# f1c100s register map
Vendor: Allwinner; File version: 1.0
Registers are 32-bit, read-write, reset 0x0 unless marked. A register's access mark holds for its fields unless they carry their own. Offsets are from the block's base; [hi:lo] are bit positions; 'fields as' and 'values as' point back to an identical list.

## CCU — Clock Control Unit - PLLs, Bus Clocks, Gating and Reset
Base 0x01C20000
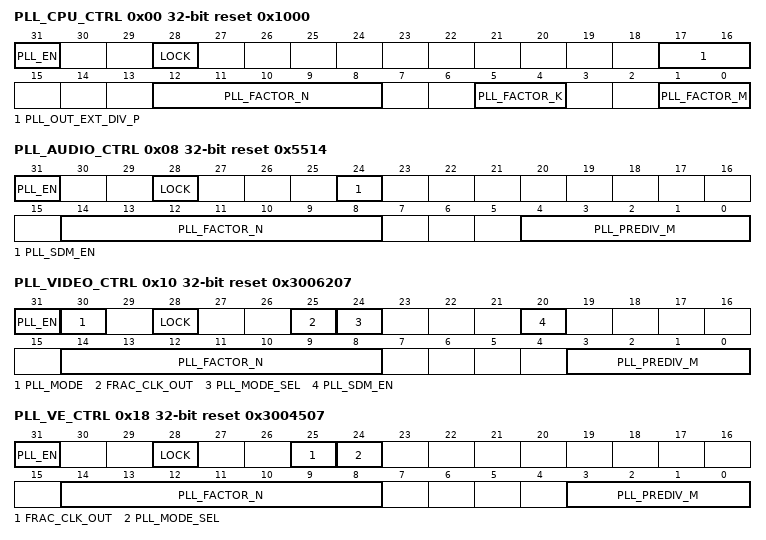
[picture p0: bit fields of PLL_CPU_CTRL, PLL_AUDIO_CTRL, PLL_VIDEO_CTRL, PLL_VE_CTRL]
0x00 PLL_CPU_CTRL reset 0x1000 — PLL CPU Control Register
  [31] PLL_EN — PLL Enable
  [28] LOCK ro — PLL Lock Status (read-only)
  [17:16] PLL_OUT_EXT_DIV_P — PLL Output External Divider P: 00=/1, 01=/2, 10=/4
  [12:8] PLL_FACTOR_N — PLL Factor N (N=Factor+1, range 1-32)
  [5:4] PLL_FACTOR_K — PLL Factor K (K=Factor+1, range 1-4)
  [1:0] PLL_FACTOR_M — PLL Factor M (M=Factor+1, range 1-4)
0x08 PLL_AUDIO_CTRL reset 0x5514 — PLL Audio Control Register
  [31] PLL_EN — PLL Enable
  [28] LOCK ro — PLL Lock Status
  [24] PLL_SDM_EN — PLL Sigma-Delta Modulation Enable
  [14:8] PLL_FACTOR_N — PLL Factor N (N=Factor+1, range 1-128)
  [4:0] PLL_PREDIV_M — PLL Pre-div Factor M (M=Factor+1, range 1-32)
0x10 PLL_VIDEO_CTRL reset 0x3006207 — PLL Video Control Register
  [31] PLL_EN — PLL Enable
  [30] PLL_MODE — PLL Mode: 0=Manual, 1=Auto (Controlled by DE)
  [28] LOCK ro — PLL Lock Status
  [25] FRAC_CLK_OUT — Fractional Clock Output: 0=270MHz, 1=297MHz
  [24] PLL_MODE_SEL — PLL Mode Select: 0=Fractional, 1=Integer
  [20] PLL_SDM_EN — PLL Sigma-Delta Modulation Enable
  [14:8] PLL_FACTOR_N — PLL Factor N (N=Factor+1, range 1-128)
  [3:0] PLL_PREDIV_M — PLL Pre-div Factor M (M=Factor+1, range 1-16)
0x18 PLL_VE_CTRL reset 0x3004507 — PLL VE Control Register
  [31] PLL_EN — PLL Enable
  [28] LOCK ro — PLL Lock Status
  [25] FRAC_CLK_OUT — Fractional Clock Output: 0=270MHz, 1=297MHz
  [24] PLL_MODE_SEL — PLL Mode Select: 0=Fractional, 1=Integer
  [14:8] PLL_FACTOR_N — PLL Factor N (N=Factor+1, range 1-128)
  [3:0] PLL_PREDIV_M — PLL Pre-div Factor M (M=Factor+1, range 1-16)
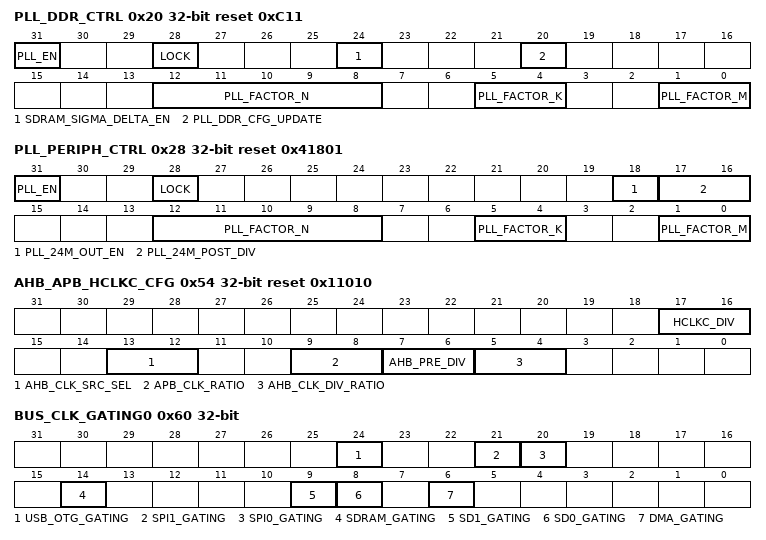
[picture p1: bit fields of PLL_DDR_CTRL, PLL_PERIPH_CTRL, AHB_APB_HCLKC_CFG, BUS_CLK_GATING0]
0x20 PLL_DDR_CTRL reset 0xC11 — PLL DDR Control Register
  [31] PLL_EN — PLL Enable
  [28] LOCK ro — PLL Lock Status
  [24] SDRAM_SIGMA_DELTA_EN — SDRAM Sigma-Delta Enable
  [20] PLL_DDR_CFG_UPDATE — PLL DDR Configuration Update
  [12:8] PLL_FACTOR_N — PLL Factor N (N=Factor+1, range 1-32)
  [5:4] PLL_FACTOR_K — PLL Factor K (K=Factor+1, range 1-4)
  [1:0] PLL_FACTOR_M — PLL Factor M (M=Factor+1, range 1-4)
0x28 PLL_PERIPH_CTRL reset 0x41801 — PLL Peripheral Control Register
  [31] PLL_EN — PLL Enable
  [28] LOCK ro — PLL Lock Status
  [18] PLL_24M_OUT_EN — PLL 24MHz Output Enable
  [17:16] PLL_24M_POST_DIV — PLL 24M Output Clock Post Divider (1/2/3/4)
  [12:8] PLL_FACTOR_N — PLL Factor N (N=Factor+1, range 1-32)
  [5:4] PLL_FACTOR_K — PLL Factor K (K=Factor+1, range 1-4)
  [1:0] PLL_FACTOR_M — PLL Factor M (M=Factor+1, range 1-4)
0x50 CPU_CLK_SRC reset 0x10000 — CPU Clock Source Register
  [17:16] CPU_CLK_SRC_SEL — CPU Clock Source Select: 00=LOSC, 01=OSC24M, 1X=PLL_CPU
0x54 AHB_APB_HCLKC_CFG reset 0x11010 — AHB/APB/HCLKC Configuration Register
  [17:16] HCLKC_DIV — HCLKC Clock Divide Ratio: 00=/1, 01=/2, 10=/3, 11=/4
  [13:12] AHB_CLK_SRC_SEL — AHB Clock Source: 00=LOSC, 01=OSC24M, 10=CPUCLK, 11=PLL_PERIPH/AHB_PREDIV
  [9:8] APB_CLK_RATIO — APB Clock Divide Ratio: 0X=/2, 10=/4, 11=/8
  [7:6] AHB_PRE_DIV — AHB Clock Pre-divide Ratio: 00=/1, 01=/2, 10=/3, 11=/4
  [5:4] AHB_CLK_DIV_RATIO — AHB Clock Divide Ratio: 00=/1, 01=/2, 10=/4, 11=/8
0x60 BUS_CLK_GATING0 — Bus Clock Gating Register 0
  [24] USB_OTG_GATING — Gating Clock For USB-OTG
  [21] SPI1_GATING — Gating Clock For SPI1
  [20] SPI0_GATING — Gating Clock For SPI0
  [14] SDRAM_GATING — Gating Clock For SDRAM
  [9] SD1_GATING — Gating Clock For SD1
  [8] SD0_GATING — Gating Clock For SD0
  [6] DMA_GATING — Gating Clock For DMA
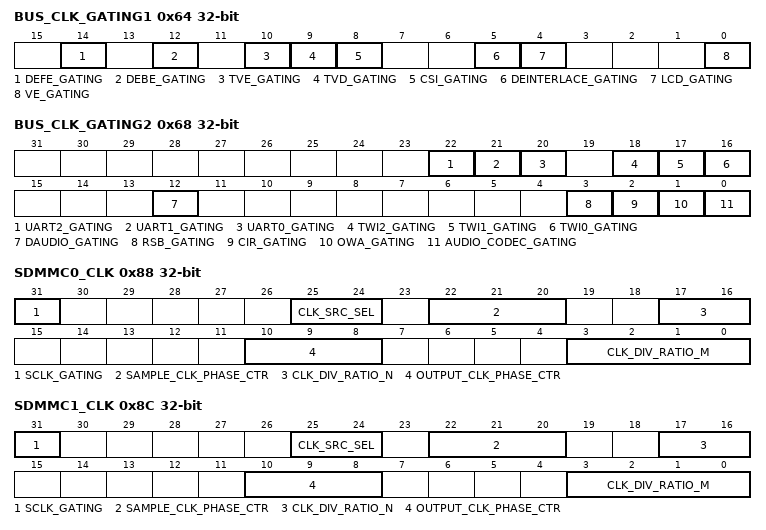
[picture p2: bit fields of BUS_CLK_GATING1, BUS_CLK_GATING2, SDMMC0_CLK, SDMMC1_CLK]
0x64 BUS_CLK_GATING1 — Bus Clock Gating Register 1
  [14] DEFE_GATING — Gating Clock For DEFE
  [12] DEBE_GATING — Gating Clock For DEBE
  [10] TVE_GATING — Gating Clock For TVE
  [9] TVD_GATING — Gating Clock For TVD
  [8] CSI_GATING — Gating Clock For CSI
  [5] DEINTERLACE_GATING — Gating Clock For DE Interlacer
  [4] LCD_GATING — Gating Clock For LCD
  [0] VE_GATING — Gating Clock For VE
0x68 BUS_CLK_GATING2 — Bus Clock Gating Register 2
  [22] UART2_GATING — Gating Clock For UART2
  [21] UART1_GATING — Gating Clock For UART1
  [20] UART0_GATING — Gating Clock For UART0
  [18] TWI2_GATING — Gating Clock For TWI2
  [17] TWI1_GATING — Gating Clock For TWI1
  [16] TWI0_GATING — Gating Clock For TWI0
  [12] DAUDIO_GATING — Gating Clock For DAUDIO
  [3] RSB_GATING — Gating Clock For RSB
  [2] CIR_GATING — Gating Clock For CIR
  [1] OWA_GATING — Gating Clock For OWA
  [0] AUDIO_CODEC_GATING — Gating Clock For AUDIOCODEC
0x88 SDMMC0_CLK — SDMMC0 Clock Register
  [31] SCLK_GATING — Gating Special Clock
  [25:24] CLK_SRC_SEL — Clock Source Select: 00=OSC24M, 01=PLL_PERIPH
  [22:20] SAMPLE_CLK_PHASE_CTR — Sample Clock Phase Control (0-7)
  [17:16] CLK_DIV_RATIO_N — Clock Pre-Divide Ratio N (2^n, divider 1/2/4/8)
  [10:8] OUTPUT_CLK_PHASE_CTR — Output Clock Phase Control (0-7)
  [3:0] CLK_DIV_RATIO_M — Clock Divide Ratio M (m+1, divider 1-16)
0x8C SDMMC1_CLK — SDMMC1 Clock Register
  fields as SDMMC0_CLK
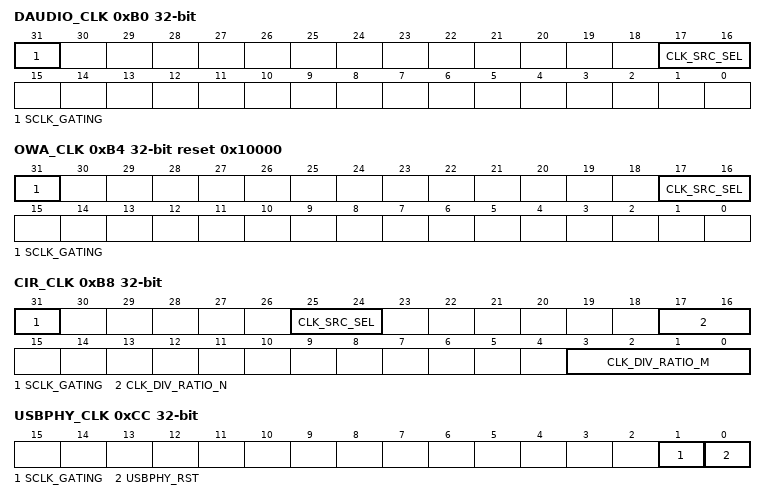
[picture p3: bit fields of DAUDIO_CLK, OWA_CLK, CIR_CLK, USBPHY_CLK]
0xB0 DAUDIO_CLK — DAUDIO Clock Register
  [31] SCLK_GATING — Gating Special Clock
  [17:16] CLK_SRC_SEL — Clock Source: 00=PLL_AUDIO(8X), 01=PLL_AUDIO(8X)/2, 10=PLL_AUDIO(8X)/4, 11=PLL_AUDIO(8X)/8
0xB4 OWA_CLK reset 0x10000 — OWA Clock Register
  [31] SCLK_GATING — Gating Special Clock
  [17:16] CLK_SRC_SEL — Clock Source: 00=PLL2(8X), 01=PLL2(8X)/2, 10=PLL2(8X)/4, 11=PLL2(8X)/8
0xB8 CIR_CLK — CIR Clock Register
  [31] SCLK_GATING — Gating Special Clock
  [25:24] CLK_SRC_SEL — Clock Source Select: 00=LOSC, 01=OSC24M
  [17:16] CLK_DIV_RATIO_N — Clock Pre-divide Ratio N (2^n, divider 1/2/4/8)
  [3:0] CLK_DIV_RATIO_M — Clock Divide Ratio M (m+1, divider 1-16)
0xCC USBPHY_CLK — USBPHY Clock Register
  [1] SCLK_GATING — USBPHY 24MHz Clock Gating
  [0] USBPHY_RST — USB PHY Reset Control: 0=Assert, 1=De-assert
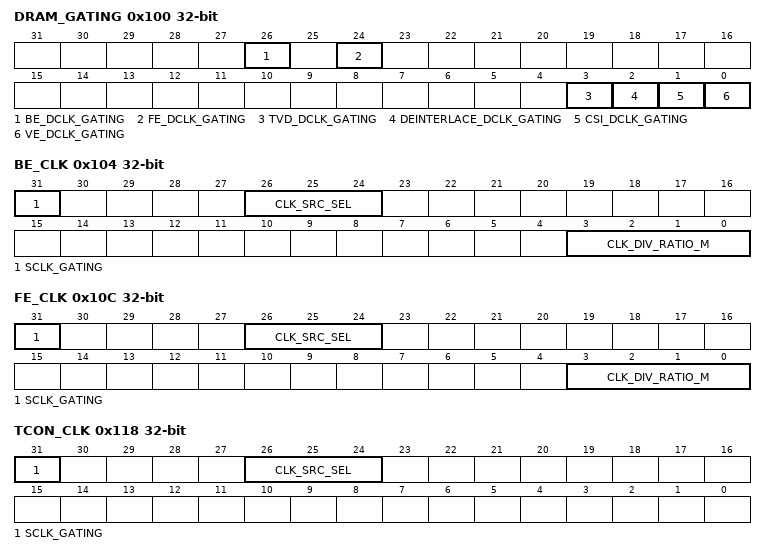
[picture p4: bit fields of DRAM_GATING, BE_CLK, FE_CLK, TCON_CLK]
0x100 DRAM_GATING
  [26] BE_DCLK_GATING — Gating DRAM SCLK(1X) For BE
  [24] FE_DCLK_GATING — Gating DRAM SCLK(1X) For FE
  [3] TVD_DCLK_GATING — Gating DRAM SCLK(1X) For TVD
  [2] DEINTERLACE_DCLK_GATING — Gating DRAM SCLK(1X) For DEINTERLACE
  [1] CSI_DCLK_GATING — Gating DRAM SCLK(1X) For CSI
  [0] VE_DCLK_GATING — Gating DRAM SCLK(1X) For VE
0x104 BE_CLK — BE Clock Register
  [31] SCLK_GATING — Gating Special Clock
  [26:24] CLK_SRC_SEL — Clock Source: 000=PLL_VIDEO, 010=PLL_PERIPH
  [3:0] CLK_DIV_RATIO_M — Clock Divide Ratio M (m+1, divider 1-16)
0x10C FE_CLK — FE Clock Register
  fields as BE_CLK
0x118 TCON_CLK — TCON Clock Register
  [31] SCLK_GATING — Gating Special Clock
  [26:24] CLK_SRC_SEL — Clock Source: 000=PLL_VIDEO(1X), 010=PLL_VIDEO(2X)
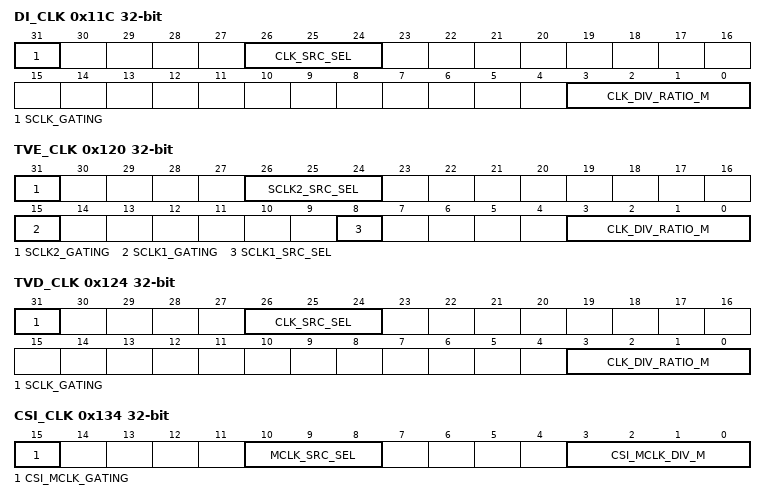
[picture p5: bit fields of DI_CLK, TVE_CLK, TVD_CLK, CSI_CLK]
0x11C DI_CLK — De-interlacer Clock Register
  [31] SCLK_GATING — Gating Special Clock
  [26:24] CLK_SRC_SEL — Clock Source: 000=PLL_VIDEO(1X), 010=PLL_VIDEO(2X)
  [3:0] CLK_DIV_RATIO_M — Clock Divide Ratio M (m+1, divider 1-16)
0x120 TVE_CLK — TVE Clock Register
  [31] SCLK2_GATING — Gating Special Clock 2
  [26:24] SCLK2_SRC_SEL — SClock2 Source: 000=PLL_VIDEO(1X), 010=PLL_VIDEO(2X)
  [15] SCLK1_GATING — Gating Special Clock 1
  [8] SCLK1_SRC_SEL — SClock1 Source: 0=TVE_SCLK2, 1=TVE_SCLK2/2
  [3:0] CLK_DIV_RATIO_M — Clock Divide Ratio M (m+1, divider 1-16)
0x124 TVD_CLK — TVD Clock Register
  [31] SCLK_GATING — Gating Special Clock
  [26:24] CLK_SRC_SEL — Clock Source: 000=PLL_VIDEO(1X), 001=OSC24M, 010=PLL_VIDEO(2X)
  [3:0] CLK_DIV_RATIO_M — Clock Divide Ratio M (m+1, divider 1-16)
0x134 CSI_CLK — CSI Clock Register
  [15] CSI_MCLK_GATING — Gating Master Clock
  [10:8] MCLK_SRC_SEL — Master Clock Source: 000=PLL_VIDEO(1X), 101=OSC24M
  [3:0] CSI_MCLK_DIV_M — CSI Master Clock Divide Ratio M (m+1, divider 1-16)
0x13C VE_CLK — VE Clock Register
  [31] SCLK_GATING — Gating Special Clock (SCLK=PLL_VE output)
0x140 AUDIO_CODEC_CLK — Audio Codec Clock Register
  [31] SCLK_GATING — Gating Special Clock (SCLK=PLL_AUDIO output)
0x144 AVS_CLK — AVS Clock Register
  [31] SCLK_GATING — Gating Special Clock (SCLK=OSC24M)
0x200 PLL_STABLE_TIME0 reset 0xFF — PLL Stable Time Register 0
  [15:0] PLL_LOCK_TIME — PLL Lock Time (Unit: us)
0x204 PLL_STABLE_TIME1 reset 0xFF — PLL Stable Time Register 1
  [15:0] PLL_CPU_LOCK_TIME — PLL CPU Lock Time (Unit: us)
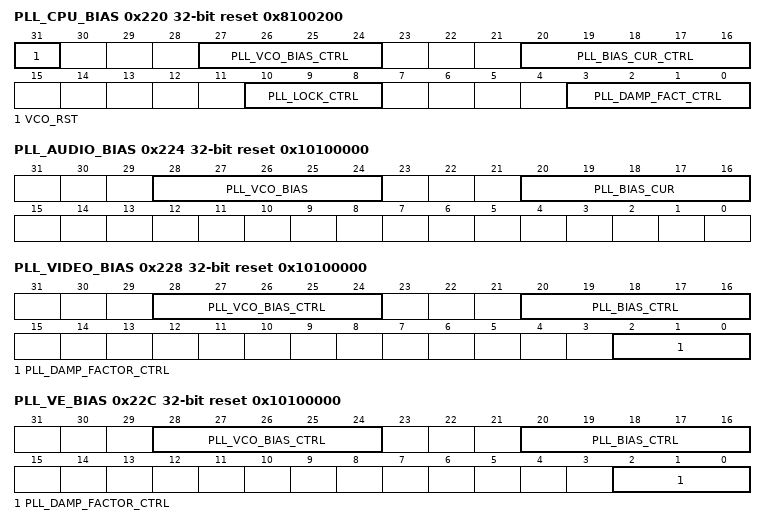
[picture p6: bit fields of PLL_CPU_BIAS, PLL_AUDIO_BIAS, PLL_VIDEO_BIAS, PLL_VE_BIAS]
0x220 PLL_CPU_BIAS reset 0x8100200
  [31] VCO_RST — VCO Reset In
  [27:24] PLL_VCO_BIAS_CTRL — PLL VCO Bias Control[3:0]
  [20:16] PLL_BIAS_CUR_CTRL — PLL Bias Current Control[4:0]
  [10:8] PLL_LOCK_CTRL — PLL Lock Time Control[2:0]
  [3:0] PLL_DAMP_FACT_CTRL — PLL Damping Factor Control[3:0]
0x224 PLL_AUDIO_BIAS reset 0x10100000
  [28:24] PLL_VCO_BIAS — PLL VCO Bias Current[4:0]
  [20:16] PLL_BIAS_CUR — PLL Bias Current[4:0]
0x228 PLL_VIDEO_BIAS reset 0x10100000
  [28:24] PLL_VCO_BIAS_CTRL — PLL VCO Bias Control[4:0]
  [20:16] PLL_BIAS_CTRL — PLL Bias Control[4:0]
  [2:0] PLL_DAMP_FACTOR_CTRL — PLL Damping Factor Control[2:0]
0x22C PLL_VE_BIAS reset 0x10100000
  fields as PLL_VIDEO_BIAS
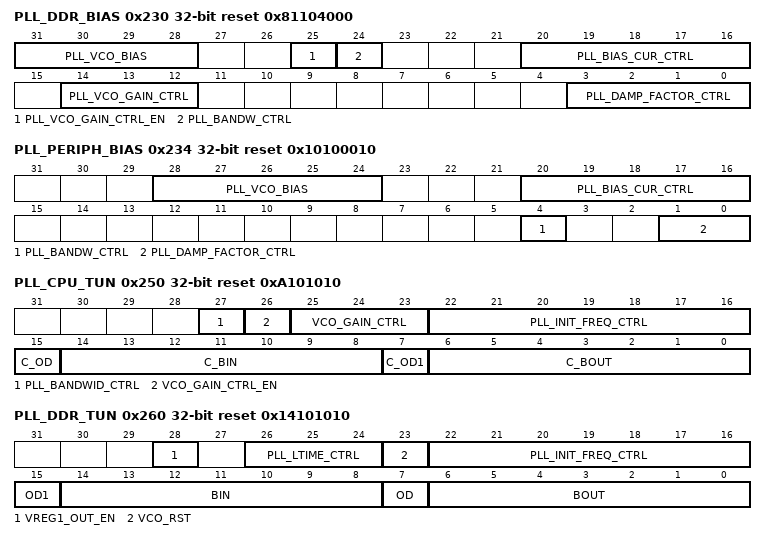
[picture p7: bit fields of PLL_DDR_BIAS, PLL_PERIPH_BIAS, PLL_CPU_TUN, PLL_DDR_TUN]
0x230 PLL_DDR_BIAS reset 0x81104000
  [31:28] PLL_VCO_BIAS — PLL VCO Bias[3:0]
  [25] PLL_VCO_GAIN_CTRL_EN — PLL VCO Gain Control Enable
  [24] PLL_BANDW_CTRL — PLL Band Width Control: 0=Narrow, 1=Wide
  [20:16] PLL_BIAS_CUR_CTRL — PLL Bias Current Control
  [14:12] PLL_VCO_GAIN_CTRL — PLL VCO Gain Control Bit[2:0]
  [3:0] PLL_DAMP_FACTOR_CTRL — PLL Damping Factor Control[3:0]
0x234 PLL_PERIPH_BIAS reset 0x10100010 — PLL Peripheral Bias Register
  [28:24] PLL_VCO_BIAS — PLL VCO Bias[4:0]
  [20:16] PLL_BIAS_CUR_CTRL — PLL Bias Current Control
  [4] PLL_BANDW_CTRL — PLL Band Width Control: 0=Narrow, 1=Wide
  [1:0] PLL_DAMP_FACTOR_CTRL — PLL Damping Factor Control[1:0]
0x250 PLL_CPU_TUN reset 0xA101010 — PLL CPU Tuning Register
  [27] PLL_BANDWID_CTRL — PLL Band Width Control: 0=Narrow, 1=Wide
  [26] VCO_GAIN_CTRL_EN — VCO Gain Control Enable
  [25:23] VCO_GAIN_CTRL — VCO Gain Control Bits[2:0]
  [22:16] PLL_INIT_FREQ_CTRL — PLL Initial Frequency Control[6:0]
  [15] C_OD — C-Reg-Od For Verify
  [14:8] C_BIN — C-B-In[6:0] For Verify
  [7] C_OD1 — C-Reg-Od1 For Verify
  [6:0] C_BOUT ro — C-B-Out[6:0] For Verify (read-only)
0x260 PLL_DDR_TUN reset 0x14101010 — PLL DDR Tuning Register
  [28] VREG1_OUT_EN — Vreg1 Out Enable
  [26:24] PLL_LTIME_CTRL — PLL Lock Time Control[2:0]
  [23] VCO_RST — VCO Reset In
  [22:16] PLL_INIT_FREQ_CTRL — PLL Initial Frequency Control[6:0]
  [15] OD1 — Reg-Od1 For Verify
  [14:8] BIN — B-In[6:0] For Verify
  [7] OD — Reg-Od For Verify
  [6:0] BOUT ro — B-Out[6:0] For Verify (read-only)
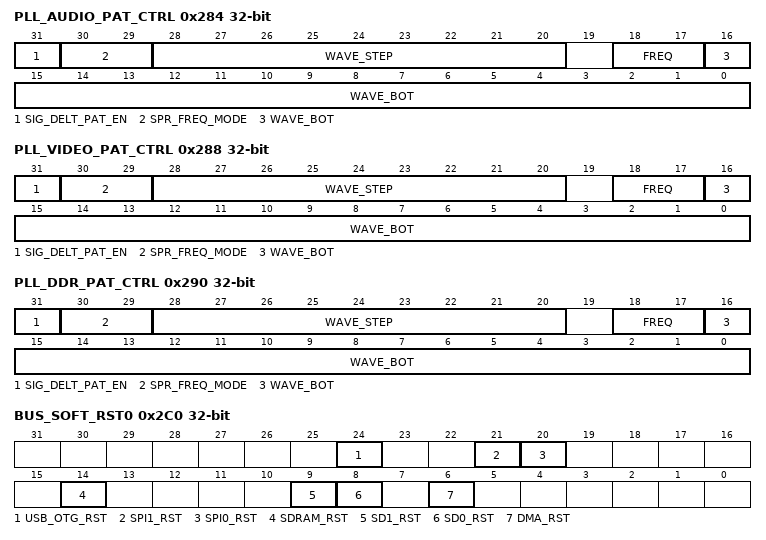
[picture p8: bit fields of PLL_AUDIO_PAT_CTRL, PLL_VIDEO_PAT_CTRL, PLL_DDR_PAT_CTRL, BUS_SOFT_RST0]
0x284 PLL_AUDIO_PAT_CTRL — PLL Audio Pattern Control Register
  [31] SIG_DELT_PAT_EN — Sigma-Delta Pattern Enable
  [30:29] SPR_FREQ_MODE — Spread Frequency Mode: 00=DC=0, 01=DC=1, 1X=Triangular
  [28:20] WAVE_STEP
  [18:17] FREQ — Frequency: 00=31.5KHz, 01=32KHz, 10=32.5KHz, 11=33KHz
  [16:0] WAVE_BOT — Wave Bottom
0x288 PLL_VIDEO_PAT_CTRL — PLL Video Pattern Control Register
  fields as PLL_AUDIO_PAT_CTRL
0x290 PLL_DDR_PAT_CTRL — PLL DDR Pattern Control Register
  fields as PLL_AUDIO_PAT_CTRL
0x2C0 BUS_SOFT_RST0 — Bus Software Reset Register 0
  [24] USB_OTG_RST — USB OTG Reset: 0=Assert, 1=De-assert
  [21] SPI1_RST — SPI1 Reset: 0=Assert, 1=De-assert
  [20] SPI0_RST — SPI0 Reset: 0=Assert, 1=De-assert
  [14] SDRAM_RST — SDRAM Reset: 0=Assert, 1=De-assert
  [9] SD1_RST — SD/MMC 1 Reset: 0=Assert, 1=De-assert
  [8] SD0_RST — SD/MMC 0 Reset: 0=Assert, 1=De-assert
  [6] DMA_RST — DMA Reset: 0=Assert, 1=De-assert
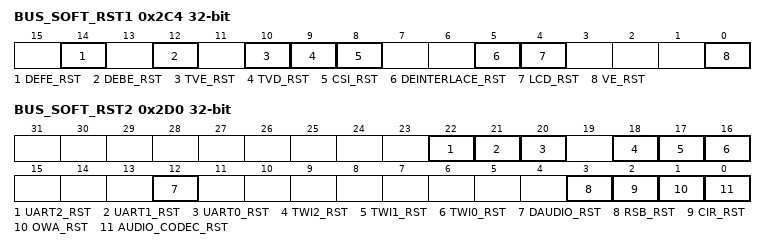
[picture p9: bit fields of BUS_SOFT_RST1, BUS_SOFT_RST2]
0x2C4 BUS_SOFT_RST1 — Bus Software Reset Register 1
  [14] DEFE_RST — DEFE Reset: 0=Assert, 1=De-assert
  [12] DEBE_RST — DEBE Reset: 0=Assert, 1=De-assert
  [10] TVE_RST — TVE Reset: 0=Assert, 1=De-assert
  [9] TVD_RST — TVD Reset: 0=Assert, 1=De-assert
  [8] CSI_RST — CSI Reset: 0=Assert, 1=De-assert
  [5] DEINTERLACE_RST — DEINTERLACE Reset: 0=Assert, 1=De-assert
  [4] LCD_RST — LCD Reset: 0=Assert, 1=De-assert
  [0] VE_RST — VE Reset: 0=Assert, 1=De-assert
0x2D0 BUS_SOFT_RST2 — Bus Software Reset Register 2
  [22] UART2_RST — UART2 Reset: 0=Assert, 1=De-assert
  [21] UART1_RST — UART1 Reset: 0=Assert, 1=De-assert
  [20] UART0_RST — UART0 Reset: 0=Assert, 1=De-assert
  [18] TWI2_RST — TWI2 Reset: 0=Assert, 1=De-assert
  [17] TWI1_RST — TWI1 Reset: 0=Assert, 1=De-assert
  [16] TWI0_RST — TWI0 Reset: 0=Assert, 1=De-assert
  [12] DAUDIO_RST — DAUDIO Reset: 0=Assert, 1=De-assert
  [3] RSB_RST — RSB Reset: 0=Assert, 1=De-assert
  [2] CIR_RST — CIR Reset: 0=Assert, 1=De-assert
  [1] OWA_RST — OWA Reset: 0=Assert, 1=De-assert
  [0] AUDIO_CODEC_RST — AUDIOCODEC Reset: 0=Assert, 1=De-assert
